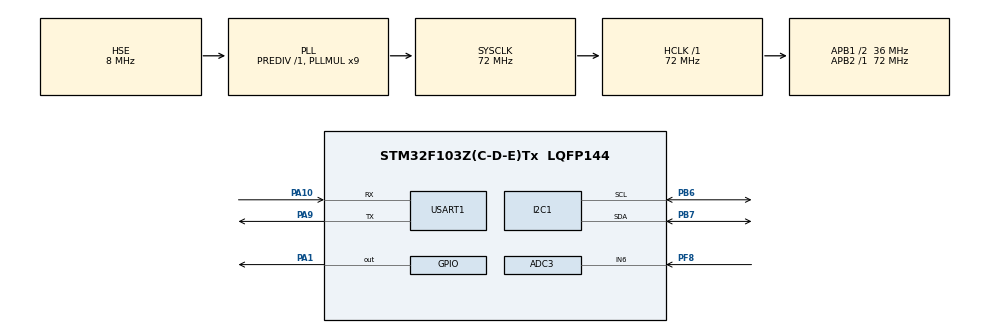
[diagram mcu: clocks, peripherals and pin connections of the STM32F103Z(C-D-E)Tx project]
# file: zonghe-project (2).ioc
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ADC3.Channel-0\#ChannelRegularConversion=ADC_CHANNEL_6
ADC3.NbrOfConversionFlag=1
ADC3.Rank-0\#ChannelRegularConversion=1
ADC3.SamplingTime-0\#ChannelRegularConversion=ADC_SAMPLETIME_1CYCLE_5
Mcu.Family=STM32F1
Mcu.Name=STM32F103Z(C-D-E)Tx
Mcu.Package=LQFP144
NVIC.ADC3_IRQn=true\:0\:0\:false\:false\:true\:true\:true
NVIC.I2C1_ER_IRQn=true\:0\:0\:false\:false\:true\:true\:true
NVIC.I2C1_EV_IRQn=true\:0\:0\:false\:false\:true\:true\:true
NVIC.PriorityGroup=NVIC_PRIORITYGROUP_4
NVIC.TIM2_IRQn=true\:0\:0\:false\:false\:true\:true\:true
NVIC.USART1_IRQn=true\:0\:0\:false\:false\:true\:true\:true
OSC_IN.Mode=HSE-External-Oscillator
OSC_IN.Signal=RCC_OSC_IN
OSC_OUT.Mode=HSE-External-Oscillator
OSC_OUT.Signal=RCC_OSC_OUT
PA1.Signal=GPIO_Output
PA10.Mode=Asynchronous
PA10.Signal=USART1_RX
PA13.Mode=Serial_Wire
PA13.Signal=SYS_JTMS-SWDIO
PA14.Mode=Serial_Wire
PA14.Signal=SYS_JTCK-SWCLK
PA9.Mode=Asynchronous
PA9.Signal=USART1_TX
PB6.Mode=I2C
PB6.Signal=I2C1_SCL
PB7.Mode=I2C
PB7.Signal=I2C1_SDA
PC14-OSC32_IN.Mode=LSE-External-Oscillator
PC14-OSC32_IN.Signal=RCC_OSC32_IN
PC15-OSC32_OUT.Mode=LSE-External-Oscillator
PC15-OSC32_OUT.Signal=RCC_OSC32_OUT
PF8.Mode=IN6
PF8.Signal=ADC3_IN6
ProjectManager.HeapSize=0x200
ProjectManager.StackSize=0x400
ProjectManager.TargetToolchain=MDK-ARM V5
RCC.ADCPresc=RCC_ADCPCLK2_DIV6
RCC.AHBFreq_Value=72000000
RCC.APB1CLKDivider=RCC_HCLK_DIV2
RCC.APB1Freq_Value=36000000
RCC.APB1TimFreq_Value=72000000
RCC.APB2Freq_Value=72000000
RCC.APB2TimFreq_Value=72000000
RCC.HCLKFreq_Value=72000000
RCC.PLLMUL=RCC_PLL_MUL9
RCC.PLLSourceVirtual=RCC_PLLSOURCE_HSE
RCC.SYSCLKFreq_VALUE=72000000
RCC.SYSCLKSource=RCC_SYSCLKSOURCE_PLLCLK
RCC.USBFreq_Value=72000000
TIM2.Prescaler=72-1
USART1.VirtualMode=VM_ASYNC
VP_TIM2_VS_ClockSourceINT.Mode=Internal
board=custom

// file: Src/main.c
/* USER CODE BEGIN Header */
/**
  ******************************************************************************
  * @file           : main.c
  * @brief          : Main program body
  ******************************************************************************
  * @attention
  *
  * <h2><center>&copy; Copyright (c) 2024 STMicroelectronics.
  * All rights reserved.</center></h2>
  *
  * This software component is licensed by ST under BSD 3-Clause license,
  * the "License"; You may not use this file except in compliance with the
  * License. You may obtain a copy of the License at:
  *                        opensource.org/licenses/BSD-3-Clause
  *
  ******************************************************************************
  */
/* USER CODE END Header */

#include "main.h"
#include "adc.h"
#include "i2c.h"
#include "tim.h"
#include "usart.h"
#include "gpio.h"
#include "oled.h"
#include "DHT11.h"

/* USER CODE BEGIN Includes */
#include "stdio.h"
#include "dht11.h"
/* USER CODE END Includes */

void SystemClock_Config(void);
/* USER CODE BEGIN PFP */

char Humiditystring[50];
char Tempstring[50];
char error_message[50];
char lsens_string[50];
typedef unsigned char u8;
float adcx;
uint16_t temperature;
uint16_t humidity;

/* USER CODE END PFP */

int main(void)
{

  /* MCU Configuration--------------------------------------------------------*/

  /* Reset of all peripherals, Initializes the Flash interface and the Systick. */
  HAL_Init();

  /* Configure the system clock */
  SystemClock_Config();

  /* Initialize all configured peripherals */
  MX_GPIO_Init();
  MX_ADC3_Init();
  MX_I2C1_Init();
  MX_TIM2_Init();
  MX_USART1_UART_Init();

/*********** OLED初始化 ***********/

  OLED_Init();  // 初始化 OLED 显示屏
  OLED_Clear();  // 清空 OLED 屏幕

/*********** OLED初始化 ***********/

	while(1)
	{
		/*********** 温湿度传感器 ***********/
		DHT11_Read_Data(&temperature,&humidity);
		sprintf(Tempstring, "Temp: %d.%d ", temperature >> 8, temperature & 0xff);
		sprintf(Humiditystring, "Humidity: %d.%d%% ", humidity >> 8, humidity & 0xff);

		OLED_ShowString(0,0,Tempstring,16);
		OLED_ShowString(0,3,Humiditystring,16);

		/*********** 光敏传感器 ***********/
    adcx=Lsenes_Get_Val();
		sprintf(lsens_string, "lsens_val: %.2f", adcx);
		OLED_ShowString(0,6,lsens_string,16);
		OLED_ShowNum(10 * 8, 6, adcx, 3, 16);

    // 串口输出文字
		HAL_UART_Transmit(&huart1, (uint8_t*)Tempstring, strlen(Tempstring), 1000);
    HAL_UART_Transmit(&huart1, (uint8_t*)Humiditystring, strlen(Humiditystring), 1000);
    HAL_UART_Transmit(&huart1, (uint8_t*)lsens_string, strlen(lsens_string), 1000);

    // 延时 1 秒（控制更新频率）
    HAL_Delay(1000);

	}

}

/*********** 温湿度传感器 ***********/

void SystemClock_Config(void)
{
  RCC_OscInitTypeDef RCC_OscInitStruct = {0};
  RCC_ClkInitTypeDef RCC_ClkInitStruct = {0};
  RCC_PeriphCLKInitTypeDef PeriphClkInit = {0};

  /** Initializes the CPU, AHB and APB busses clocks
  */
  RCC_OscInitStruct.OscillatorType = RCC_OSCILLATORTYPE_HSE;
  RCC_OscInitStruct.HSEState = RCC_HSE_ON;
  RCC_OscInitStruct.HSEPredivValue = RCC_HSE_PREDIV_DIV1;
  RCC_OscInitStruct.HSIState = RCC_HSI_ON;
  RCC_OscInitStruct.PLL.PLLState = RCC_PLL_ON;
  RCC_OscInitStruct.PLL.PLLSource = RCC_PLLSOURCE_HSE;
  RCC_OscInitStruct.PLL.PLLMUL = RCC_PLL_MUL9;
  if (HAL_RCC_OscConfig(&RCC_OscInitStruct) != HAL_OK)
  {
    Error_Handler();
  }
  /** Initializes the CPU, AHB and APB busses clocks
  */
  RCC_ClkInitStruct.ClockType = RCC_CLOCKTYPE_HCLK|RCC_CLOCKTYPE_SYSCLK
                              |RCC_CLOCKTYPE_PCLK1|RCC_CLOCKTYPE_PCLK2;
  RCC_ClkInitStruct.SYSCLKSource = RCC_SYSCLKSOURCE_PLLCLK;
  RCC_ClkInitStruct.AHBCLKDivider = RCC_SYSCLK_DIV1;
  RCC_ClkInitStruct.APB1CLKDivider = RCC_HCLK_DIV2;
  RCC_ClkInitStruct.APB2CLKDivider = RCC_HCLK_DIV1;

  if (HAL_RCC_ClockConfig(&RCC_ClkInitStruct, FLASH_LATENCY_2) != HAL_OK)
  {
    Error_Handler();
  }
  PeriphClkInit.PeriphClockSelection = RCC_PERIPHCLK_ADC;
  PeriphClkInit.AdcClockSelection = RCC_ADCPCLK2_DIV6;
  if (HAL_RCCEx_PeriphCLKConfig(&PeriphClkInit) != HAL_OK)
  {
    Error_Handler();
  }
}

void Error_Handler(void)
{
}

/************************ (C) COPYRIGHT STMicroelectronics *****END OF FILE****/
